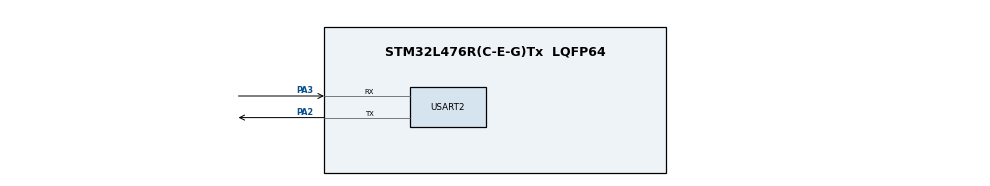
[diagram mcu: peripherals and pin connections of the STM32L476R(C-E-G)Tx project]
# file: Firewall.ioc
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Mcu.Family=STM32L4
Mcu.Name=STM32L476R(C-E-G)Tx
Mcu.Package=LQFP64
NVIC.PriorityGroup=NVIC_PRIORITYGROUP_4
PA13\ (JTMS-SWDIO).Mode=Trace_Asynchronous_SW
PA13\ (JTMS-SWDIO).Signal=SYS_JTMS-SWDIO
PA14\ (JTCK-SWCLK).Mode=Trace_Asynchronous_SW
PA14\ (JTCK-SWCLK).Signal=SYS_JTCK-SWCLK
PA2.Mode=Asynchronous
PA2.Signal=USART2_TX
PA3.Mode=Asynchronous
PA3.Signal=USART2_RX
PB3\ (JTDO-TRACESWO).Mode=Trace_Asynchronous_SW
PB3\ (JTDO-TRACESWO).Signal=SYS_JTDO-SWO
ProjectManager.HeapSize=0x200
ProjectManager.StackSize=0x400
ProjectManager.TargetToolchain=TrueSTUDIO
RCC.ADCFreq_Value=48000000
RCC.HSE_VALUE=8000000
RCC.HSI_VALUE=16000000
RCC.LSE_VALUE=32768
RCC.MSI_VALUE=4000000
RCC.PLLSAI1N=24
RCC.USBFreq_Value=48000000
RCC.VCOOutputFreq_Value=32000000
USART2.VirtualMode-Asynchronous=VM_ASYNC
USART2.WordLength=WORDLENGTH_8B
VP_RNG_VS_RNG.Mode=RNG_Activate
board=Firewall

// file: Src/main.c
/**
  ******************************************************************************
  * File Name          : main.c
  * Description        : Main program body
  ******************************************************************************
  ** This notice applies to any and all portions of this file
  * that are not between comment pairs USER CODE BEGIN and
  * USER CODE END. Other portions of this file, whether
  * inserted by the user or by software development tools
  * are owned by their respective copyright owners.
  *
  * COPYRIGHT(c) 2017 STMicroelectronics
  *
  * Redistribution and use in source and binary forms, with or without modification,
  * are permitted provided that the following conditions are met:
  *   1. Redistributions of source code must retain the above copyright notice,
  *      this list of conditions and the following disclaimer.
  *   2. Redistributions in binary form must reproduce the above copyright notice,
  *      this list of conditions and the following disclaimer in the documentation
  *      and/or other materials provided with the distribution.
  *   3. Neither the name of STMicroelectronics nor the names of its contributors
  *      may be used to endorse or promote products derived from this software
  *      without specific prior written permission.
  *
  * THIS SOFTWARE IS PROVIDED BY THE COPYRIGHT HOLDERS AND CONTRIBUTORS "AS IS"
  * AND ANY EXPRESS OR IMPLIED WARRANTIES, INCLUDING, BUT NOT LIMITED TO, THE
  * IMPLIED WARRANTIES OF MERCHANTABILITY AND FITNESS FOR A PARTICULAR PURPOSE ARE
  * DISCLAIMED. IN NO EVENT SHALL THE COPYRIGHT HOLDER OR CONTRIBUTORS BE LIABLE
  * FOR ANY DIRECT, INDIRECT, INCIDENTAL, SPECIAL, EXEMPLARY, OR CONSEQUENTIAL
  * DAMAGES (INCLUDING, BUT NOT LIMITED TO, PROCUREMENT OF SUBSTITUTE GOODS OR
  * SERVICES; LOSS OF USE, DATA, OR PROFITS; OR BUSINESS INTERRUPTION) HOWEVER
  * CAUSED AND ON ANY THEORY OF LIABILITY, WHETHER IN CONTRACT, STRICT LIABILITY,
  * OR TORT (INCLUDING NEGLIGENCE OR OTHERWISE) ARISING IN ANY WAY OUT OF THE USE
  * OF THIS SOFTWARE, EVEN IF ADVISED OF THE POSSIBILITY OF SUCH DAMAGE.
  *
  ******************************************************************************
  */
#include "main.h"
#include "stm32l4xx_hal.h"

/* USER CODE BEGIN Includes */
#include <string.h>
#include "..\..\inc\firewall.h"

/* USER CODE END Includes */

__attribute__((section(".unittestdata"))) RNG_HandleTypeDef hrng;
__attribute__((section(".unittestdata"))) UART_HandleTypeDef huart2;

/* USER CODE BEGIN PV */
/* Private variables ---------------------------------------------------------*/

/* USER CODE END PV */

void SystemClock_Config(void);
static void MX_GPIO_Init(void);
static void MX_USART2_UART_Init(void);
static void MX_RNG_Init(void);

/* USER CODE BEGIN PFP */
/* Private function prototypes -----------------------------------------------*/

/* USER CODE END PFP */

__attribute__((section(".unittest"))) int main(void)
{

  /* USER CODE BEGIN 1 */
    unsigned int result = 0;
    DICE_Context ctx = {0};
    unsigned int sizeTab[3];
    unsigned char* dataTab[3];
    uint8_t key[9] = {0};
    uint8_t data[50] = {0};
    uint8_t digest[32] = {0};
  /* USER CODE END 1 */

  /* MCU Configuration----------------------------------------------------------*/

  /* Reset of all peripherals, Initializes the Flash interface and the Systick. */
  HAL_Init();

  /* Configure the system clock */
  SystemClock_Config();

  /* Initialize all configured peripherals */
  MX_GPIO_Init();
  MX_USART2_UART_Init();
  MX_RNG_Init();

  /* USER CODE BEGIN 2 */
  ctx.fid = DICE_FID_NOOP;
  ctx.magic = DICE_MAGIC;
  ctx.paramSize = 0;
  result = FWCALLGATE(&ctx);

  ctx.fid = DICE_FID_HalHandleTable;
  ctx.magic = DICE_MAGIC;
  ctx.paramSize = sizeof(DICE_PARAM_HalHandleTable);
  ctx.u.HalHandleTable.in.handleTable.phRng = &hrng;
  ctx.u.HalHandleTable.in.handleTable.phUart = &huart2;
  result = FWCALLGATE(&ctx);

  ctx.fid = DICE_FID_GetRandom;
  ctx.magic = DICE_MAGIC;
  ctx.paramSize = sizeof(DICE_PARAM_GetRandom);
  ctx.u.GetRandom.in.entropy = data;
  ctx.u.GetRandom.in.size = sizeof(data);
  result = FWCALLGATE(&ctx);

  ctx.fid = DICE_FID_SHA256;
  ctx.magic = DICE_MAGIC;
  ctx.paramSize = sizeof(DICE_PARAM_SHA256);
  ctx.u.SHA256.in.segments = 3;
  dataTab[0] = data;
  sizeTab[0] = sizeof(data);
  dataTab[1] = data;
  sizeTab[1] = sizeof(data);
  dataTab[2] = data;
  sizeTab[2] = sizeof(data);
  ctx.u.SHA256.in.data = dataTab;
  ctx.u.SHA256.in.size = sizeTab;
  ctx.u.SHA256.in.digest = digest;
  memset(digest, 0x00, sizeof(digest));
  result = FWCALLGATE(&ctx);

  ctx.fid = DICE_FID_GetRandom;
  ctx.magic = DICE_MAGIC;
  ctx.paramSize = sizeof(DICE_PARAM_GetRandom);
  ctx.u.GetRandom.in.entropy = key;
  ctx.u.GetRandom.in.size = sizeof(key);
  result = FWCALLGATE(&ctx);

  ctx.fid = DICE_FID_HMACSHA256;
  ctx.magic = DICE_MAGIC;
  ctx.paramSize = sizeof(DICE_PARAM_HMACSHA256);
  ctx.u.HMACSHA256.in.key = key;
  ctx.u.HMACSHA256.in.keySize = sizeof(key);
  ctx.u.HMACSHA256.in.segments = 3;
  dataTab[0] = data;
  sizeTab[0] = sizeof(data);
  dataTab[1] = data;
  sizeTab[1] = sizeof(data);
  dataTab[2] = data;
  sizeTab[2] = sizeof(data);
  ctx.u.HMACSHA256.in.data = dataTab;
  ctx.u.HMACSHA256.in.dataSize = sizeTab;
  ctx.u.HMACSHA256.in.hmac = digest;
  memset(digest, 0x00, sizeof(digest));
  result = FWCALLGATE(&ctx);
  /* USER CODE END 2 */

  /* Infinite loop */
  while (1)
  {

  }

}

/** System Clock Configuration
*/
__attribute__((section(".unittest"))) void SystemClock_Config(void)
{

  RCC_OscInitTypeDef RCC_OscInitStruct;
  RCC_ClkInitTypeDef RCC_ClkInitStruct;
  RCC_PeriphCLKInitTypeDef PeriphClkInit;

    /**Initializes the CPU, AHB and APB busses clocks
    */
  RCC_OscInitStruct.OscillatorType = RCC_OSCILLATORTYPE_MSI;
  RCC_OscInitStruct.MSIState = RCC_MSI_ON;
  RCC_OscInitStruct.MSICalibrationValue = 0;
  RCC_OscInitStruct.MSIClockRange = RCC_MSIRANGE_6;
  RCC_OscInitStruct.PLL.PLLState = RCC_PLL_NONE;
  if (HAL_RCC_OscConfig(&RCC_OscInitStruct) != HAL_OK)
  {
    _Error_Handler(__FILE__, __LINE__);
  }

    /**Initializes the CPU, AHB and APB busses clocks
    */
  RCC_ClkInitStruct.ClockType = RCC_CLOCKTYPE_HCLK|RCC_CLOCKTYPE_SYSCLK
                              |RCC_CLOCKTYPE_PCLK1|RCC_CLOCKTYPE_PCLK2;
  RCC_ClkInitStruct.SYSCLKSource = RCC_SYSCLKSOURCE_MSI;
  RCC_ClkInitStruct.AHBCLKDivider = RCC_SYSCLK_DIV1;
  RCC_ClkInitStruct.APB1CLKDivider = RCC_HCLK_DIV1;
  RCC_ClkInitStruct.APB2CLKDivider = RCC_HCLK_DIV1;

  if (HAL_RCC_ClockConfig(&RCC_ClkInitStruct, FLASH_LATENCY_0) != HAL_OK)
  {
    _Error_Handler(__FILE__, __LINE__);
  }

  PeriphClkInit.PeriphClockSelection = RCC_PERIPHCLK_USART2|RCC_PERIPHCLK_RNG;
  PeriphClkInit.Usart2ClockSelection = RCC_USART2CLKSOURCE_PCLK1;
  PeriphClkInit.RngClockSelection = RCC_RNGCLKSOURCE_PLLSAI1;
  PeriphClkInit.PLLSAI1.PLLSAI1Source = RCC_PLLSOURCE_MSI;
  PeriphClkInit.PLLSAI1.PLLSAI1M = 1;
  PeriphClkInit.PLLSAI1.PLLSAI1N = 24;
  PeriphClkInit.PLLSAI1.PLLSAI1P = RCC_PLLP_DIV7;
  PeriphClkInit.PLLSAI1.PLLSAI1Q = RCC_PLLQ_DIV2;
  PeriphClkInit.PLLSAI1.PLLSAI1R = RCC_PLLR_DIV2;
  PeriphClkInit.PLLSAI1.PLLSAI1ClockOut = RCC_PLLSAI1_48M2CLK;
  if (HAL_RCCEx_PeriphCLKConfig(&PeriphClkInit) != HAL_OK)
  {
    _Error_Handler(__FILE__, __LINE__);
  }

    /**Configure the main internal regulator output voltage
    */
  if (HAL_PWREx_ControlVoltageScaling(PWR_REGULATOR_VOLTAGE_SCALE1) != HAL_OK)
  {
    _Error_Handler(__FILE__, __LINE__);
  }

    /**Configure the Systick interrupt time
    */
  HAL_SYSTICK_Config(HAL_RCC_GetHCLKFreq()/1000);

    /**Configure the Systick
    */
  HAL_SYSTICK_CLKSourceConfig(SYSTICK_CLKSOURCE_HCLK);

  /* SysTick_IRQn interrupt configuration */
  HAL_NVIC_SetPriority(SysTick_IRQn, 0, 0);
}

/* RNG init function */
__attribute__((section(".unittest"))) static void MX_RNG_Init(void)
{

  hrng.Instance = RNG;
  if (HAL_RNG_Init(&hrng) != HAL_OK)
  {
    _Error_Handler(__FILE__, __LINE__);
  }

}

/* USART2 init function */
__attribute__((section(".unittest"))) static void MX_USART2_UART_Init(void)
{

  huart2.Instance = USART2;
  huart2.Init.BaudRate = 115200;
  huart2.Init.WordLength = UART_WORDLENGTH_8B;
  huart2.Init.StopBits = UART_STOPBITS_1;
  huart2.Init.Parity = UART_PARITY_NONE;
  huart2.Init.Mode = UART_MODE_TX_RX;
  huart2.Init.HwFlowCtl = UART_HWCONTROL_NONE;
  huart2.Init.OverSampling = UART_OVERSAMPLING_16;
  huart2.Init.OneBitSampling = UART_ONE_BIT_SAMPLE_DISABLE;
  huart2.AdvancedInit.AdvFeatureInit = UART_ADVFEATURE_NO_INIT;
  if (HAL_UART_Init(&huart2) != HAL_OK)
  {
    _Error_Handler(__FILE__, __LINE__);
  }

}

/** Configure pins as
        * Analog
        * Input
        * Output
        * EVENT_OUT
        * EXTI
*/
__attribute__((section(".unittest"))) static void MX_GPIO_Init(void)
{

  /* GPIO Ports Clock Enable */
  __HAL_RCC_GPIOA_CLK_ENABLE();
  __HAL_RCC_GPIOB_CLK_ENABLE();

}

void _Error_Handler(char * file, int line)
{
  while(1)
  {
  }
}

/************************ (C) COPYRIGHT STMicroelectronics *****END OF FILE****/
